# MKL28T7_CORE0 register map
Vendor: Freescale Semiconductor, Inc.; Series: Kinetis_L; File version: 1.6
CPU: CM0PLUS r0p0, little endian, no MPU, no FPU, VTOR, 2 interrupt priority bits
Registers are 32-bit, read-write, reset 0x0 unless marked. A register's access mark holds for its fields unless they carry their own. Offsets are from the block's base; [hi:lo] are bit positions; {n}, {i} and the like mark numbered series.

## ASMC — ASMC (Auxiliary System Mode Control) Module
Base 0x400F5000; register names take the prefix ASMC_
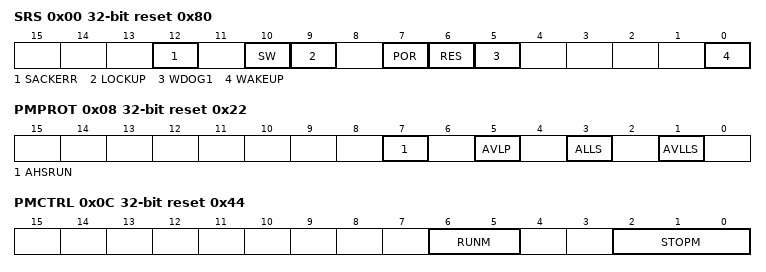
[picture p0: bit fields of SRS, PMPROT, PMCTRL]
0x00 SRS ro reset 0x80 — System Reset Status Register
  [12] SACKERR — Stop Mode Acknowledge Error Reset
    0=Reset not caused by peripheral failure to acknowledge attempt to enter stop mode; 1=Reset caused by peripheral failure to acknowledge attempt to enter stop mode
  [10] SW — Software
    0=Reset not caused by software setting of SYSRESETREQ bit; 1=Reset caused by software setting of SYSRESETREQ bit
  [9] LOCKUP — Core 1 Lockup
    0=Reset not caused by core LOCKUP event; 1=Reset caused by core LOCKUP event
  [7] POR — Power-On Reset
    0=Reset not caused by POR; 1=Reset caused by POR
  [6] RES — Chip Reset not POR
    0=Chip Reset did not occur; 1=Chip Reset caused by a source other than POR occured
  [5] WDOG1 — Watchdog
    0=Reset not caused by watchdog timeout; 1=Reset caused by watchdog timeout
  [0] WAKEUP — Low Leakage Wakeup Reset
    0=Reset not caused by LLWU module wakeup source; 1=Reset caused by LLWU module wakeup source
0x08 PMPROT reset 0x22 — Power Mode Protection register
  [7] AHSRUN — Allow High Speed Run mode
    0=HSRUN is not allowed; 1=HSRUN is allowed
  [5] AVLP — Allow Very-Low-Power Modes
    0=VLPR, VLPW, and VLPS are not allowed; 1=VLPR, VLPW, and VLPS are allowed
  [3] ALLS — Allow Low-Leakage Stop Mode
    0=Any LLSx mode is not allowed; 1=Any LLSx mode is allowed
  [1] AVLLS — Allow Very-Low-Leakage Stop Mode
    0=Any VLLSx mode is not allowed; 1=Any VLLSx mode is allowed
0x0C PMCTRL reset 0x44 — Power Mode Control register
  [6:5] RUNM — Run Mode Control
    0=Normal Run mode (RUN); 2=Very-Low-Power Run mode (VLPR); 3=High Speed Run mode (HSRUN)
  [2:0] STOPM — Stop Mode Control
    0=Normal Stop (STOP); 2=Very-Low-Power Stop (VLPS); 3=Low-Leakage Stop (LLSx); 4=Very-Low-Leakage Stop (VLLSx); 6=Reseved
0x10 STOPCTRL — Stop Control Register
  [7:6] PSTOPO — Partial Stop Option
    0=STOP - Normal Stop mode; 1=PSTOP1 - Partial Stop with both system and bus clocks disabled; 2=PSTOP2 - Partial Stop with system clock disabled and bus clock enabled
0x14 PMSTAT ro reset 0x4 — Power Mode Status register
  [7:0] PMSTAT — Power Mode Status

## MTB0 — Micro Trace Buffer
Base 0xF0000000; register names take the prefix MTB0_
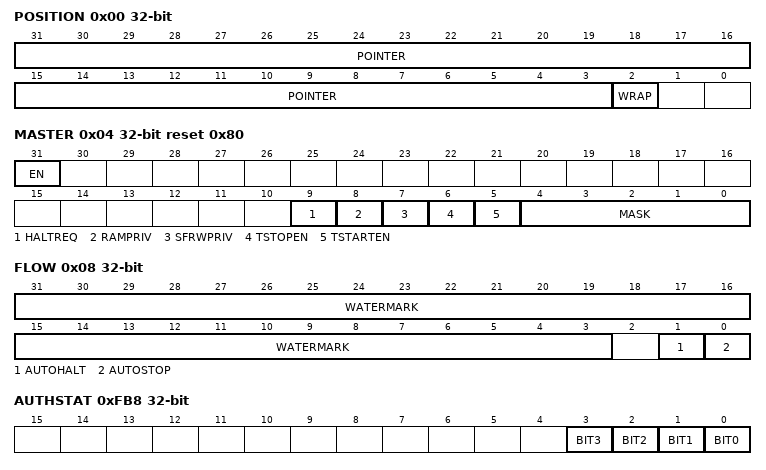
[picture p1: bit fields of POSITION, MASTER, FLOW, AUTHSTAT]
0x00 POSITION (reset mask 0x3) — MTB Position Register
  [31:3] POINTER — Trace Packet Address Pointer[28:0]
  [2] WRAP
0x04 MASTER reset 0x80 (reset mask 0xFFFFFFE0) — MTB Master Register
  [31] EN — Main Trace Enable
  [9] HALTREQ — Halt Request
  [8] RAMPRIV — RAM Privilege
  [7] SFRWPRIV — Special Function Register Write Privilege
  [6] TSTOPEN — Trace Stop Input Enable
  [5] TSTARTEN — Trace Start Input Enable
  [4:0] MASK
0x08 FLOW (reset mask 0x4) — MTB Flow Register
  [31:3] WATERMARK — WATERMARK[28:0]
  [1] AUTOHALT
  [0] AUTOSTOP
0x0C BASE ro reset not defined — MTB Base Register
  [31:0] BASEADDR
0xF00 MODECTRL ro — Integration Mode Control Register
0xFA0 TAGSET ro — Claim TAG Set Register
0xFA4 TAGCLEAR ro — Claim TAG Clear Register
0xFB0 LOCKACCESS ro
  [31:0] LOCKACCESS — Hardwired to 0x0000_0000
0xFB4 LOCKSTAT ro — Lock Status Register
0xFB8 AUTHSTAT ro — Authentication Status Register
  [3] BIT3
  [2] BIT2
  [1] BIT1
  [0] BIT0 — Connected to DBGEN.
0xFBC DEVICEARCH ro reset 0x47700A31 — Device Architecture Register
0xFC8 DEVICECFG ro — Device Configuration Register
0xFCC DEVICETYPID ro reset 0x31 — Device Type Identifier Register
0xFD0 PERIPHID{x} (x=4,5,6,7,0,1,2,3; step 0x4) ro reset not defined — Peripheral ID Register
  [31:0] PERIPHID
{0xFF0+4i} COMPID{i} (i=0..3) ro reset not defined — Component ID Register
  [31:0] COMPID — Component ID

## MTB1 — Micro Trace Buffer
Base 0xF1000000; register names take the prefix MTB1_
Registers as MTB0.
